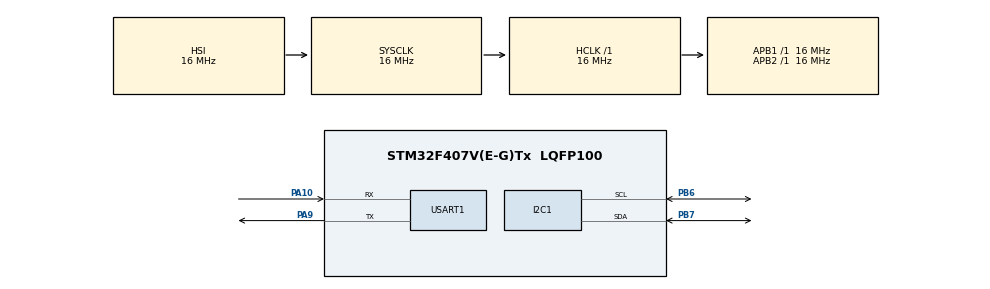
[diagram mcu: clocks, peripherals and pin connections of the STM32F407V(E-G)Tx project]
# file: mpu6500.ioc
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FREERTOS.Queues01=imuQueue,16,ImuMsg,0,Static,imuQueueBuffer,imuQueueControlBlock
FREERTOS.Tasks01=SensorTask,40,128,StartSensorTask,Default,NULL,Static,SensorTaskBuffer,SensorTaskControlBlock;TelemetryTask,24,128,StartTelemetryTask,Default,NULL,Static,TelemetryTaskBuffer,TelemetryTaskControlBlock
I2C1.I2C_Mode=I2C_Fast
Mcu.Family=STM32F4
Mcu.Name=STM32F407V(E-G)Tx
Mcu.Package=LQFP100
NVIC.PriorityGroup=NVIC_PRIORITYGROUP_4
NVIC.TIM6_DAC_IRQn=true\:15\:0\:false\:false\:true\:false\:false\:true\:true
NVIC.TimeBase=TIM6_DAC_IRQn
NVIC.TimeBaseIP=TIM6
PA10.Mode=Asynchronous
PA10.Signal=USART1_RX
PA9.Mode=Asynchronous
PA9.Signal=USART1_TX
PB6.GPIO_Pu=GPIO_PULLUP
PB6.Mode=I2C
PB6.Signal=I2C1_SCL
PB7.GPIO_Pu=GPIO_PULLUP
PB7.Mode=I2C
PB7.Signal=I2C1_SDA
ProjectManager.HeapSize=0x200
ProjectManager.StackSize=0x400
ProjectManager.TargetToolchain=CMake
RCC.AHBFreq_Value=16000000
RCC.APB1Freq_Value=16000000
RCC.APB2Freq_Value=16000000
RCC.CortexFreq_Value=16000000
RCC.HSE_VALUE=25000000
RCC.HSI_VALUE=16000000
RCC.LSE_VALUE=32768
RCC.SYSCLKFreq_VALUE=16000000
RCC.VCOOutputFreq_Value=192000000
USART1.VirtualMode=VM_ASYNC
VP_FREERTOS_VS_CMSIS_V2.Mode=CMSIS_V2
VP_SYS_VS_tim6.Mode=TIM6
board=custom

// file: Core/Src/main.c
/* USER CODE BEGIN Header */
/**
 ******************************************************************************
 * @file           : main.c
 * @brief          : Main program body
 ******************************************************************************
 * @attention
 *
 * Copyright (c) 2026 STMicroelectronics.
 * All rights reserved.
 *
 * This software is licensed under terms that can be found in the LICENSE file
 * in the root directory of this software component.
 * If no LICENSE file comes with this software, it is provided AS-IS.
 *
 ******************************************************************************
 */
/* USER CODE END Header */
#include "main.h"
#include "cmsis_os.h"

/* USER CODE BEGIN Includes */
#include "app.hpp"
#include "ImuMsg.h"

/* USER CODE END Includes */

typedef StaticTask_t osStaticThreadDef_t;
typedef StaticQueue_t osStaticMessageQDef_t;

I2C_HandleTypeDef hi2c1;

UART_HandleTypeDef huart1;

/* Definitions for SensorTask */
osThreadId_t SensorTaskHandle;
uint32_t SensorTaskBuffer[128];
osStaticThreadDef_t SensorTaskControlBlock;
const osThreadAttr_t SensorTask_attributes = {
    .name = "SensorTask",
    .cb_mem = &SensorTaskControlBlock,
    .cb_size = sizeof(SensorTaskControlBlock),
    .stack_mem = &SensorTaskBuffer[0],
    .stack_size = sizeof(SensorTaskBuffer),
    .priority = (osPriority_t)osPriorityHigh,
};
/* Definitions for TelemetryTask */
osThreadId_t TelemetryTaskHandle;
uint32_t TelemetryTaskBuffer[128];
osStaticThreadDef_t TelemetryTaskControlBlock;
const osThreadAttr_t TelemetryTask_attributes = {
    .name = "TelemetryTask",
    .cb_mem = &TelemetryTaskControlBlock,
    .cb_size = sizeof(TelemetryTaskControlBlock),
    .stack_mem = &TelemetryTaskBuffer[0],
    .stack_size = sizeof(TelemetryTaskBuffer),
    .priority = (osPriority_t)osPriorityNormal,
};
/* Definitions for imuQueue */
osMessageQueueId_t imuQueueHandle;
uint8_t imuQueueBuffer[16 * sizeof(ImuMsg)];
osStaticMessageQDef_t imuQueueControlBlock;
const osMessageQueueAttr_t imuQueue_attributes = {
    .name = "imuQueue",
    .cb_mem = &imuQueueControlBlock,
    .cb_size = sizeof(imuQueueControlBlock),
    .mq_mem = &imuQueueBuffer,
    .mq_size = sizeof(imuQueueBuffer)};

void SystemClock_Config(void);
static void MX_GPIO_Init(void);
static void MX_I2C1_Init(void);
static void MX_USART1_UART_Init(void);
void StartSensorTask(void *argument);
void StartTelemetryTask(void *argument);

int main(void)
{

  /* MCU Configuration--------------------------------------------------------*/

  /* Reset of all peripherals, Initializes the Flash interface and the Systick. */
  HAL_Init();

  /* Configure the system clock */
  SystemClock_Config();

  /* Initialize all configured peripherals */
  MX_GPIO_Init();
  MX_I2C1_Init();
  MX_USART1_UART_Init();
  /* USER CODE BEGIN 2 */
  // appMain(); // during the mpu alone test
  /* USER CODE END 2 */

  /* Init scheduler */
  osKernelInitialize();

  /* Create the queue(s) */
  /* creation of imuQueue */
  imuQueueHandle = osMessageQueueNew(16, sizeof(ImuMsg), &imuQueue_attributes);

  /* Create the thread(s) */
  /* creation of SensorTask */
  SensorTaskHandle = osThreadNew(StartSensorTask, NULL, &SensorTask_attributes);

  /* creation of TelemetryTask */
  TelemetryTaskHandle = osThreadNew(StartTelemetryTask, NULL, &TelemetryTask_attributes);

  /* Start scheduler */
  osKernelStart();

  /* We should never get here as control is now taken by the scheduler */

  /* Infinite loop */
  while (1)
  {

  }
}

void SystemClock_Config(void)
{
  RCC_OscInitTypeDef RCC_OscInitStruct = {0};
  RCC_ClkInitTypeDef RCC_ClkInitStruct = {0};

  /** Configure the main internal regulator output voltage
   */
  __HAL_RCC_PWR_CLK_ENABLE();
  __HAL_PWR_VOLTAGESCALING_CONFIG(PWR_REGULATOR_VOLTAGE_SCALE1);

  /** Initializes the RCC Oscillators according to the specified parameters
   * in the RCC_OscInitTypeDef structure.
   */
  RCC_OscInitStruct.OscillatorType = RCC_OSCILLATORTYPE_HSI;
  RCC_OscInitStruct.HSIState = RCC_HSI_ON;
  RCC_OscInitStruct.HSICalibrationValue = RCC_HSICALIBRATION_DEFAULT;
  RCC_OscInitStruct.PLL.PLLState = RCC_PLL_NONE;
  if (HAL_RCC_OscConfig(&RCC_OscInitStruct) != HAL_OK)
  {
    Error_Handler();
  }

  /** Initializes the CPU, AHB and APB buses clocks
   */
  RCC_ClkInitStruct.ClockType = RCC_CLOCKTYPE_HCLK | RCC_CLOCKTYPE_SYSCLK | RCC_CLOCKTYPE_PCLK1 | RCC_CLOCKTYPE_PCLK2;
  RCC_ClkInitStruct.SYSCLKSource = RCC_SYSCLKSOURCE_HSI;
  RCC_ClkInitStruct.AHBCLKDivider = RCC_SYSCLK_DIV1;
  RCC_ClkInitStruct.APB1CLKDivider = RCC_HCLK_DIV1;
  RCC_ClkInitStruct.APB2CLKDivider = RCC_HCLK_DIV1;

  if (HAL_RCC_ClockConfig(&RCC_ClkInitStruct, FLASH_LATENCY_0) != HAL_OK)
  {
    Error_Handler();
  }
}

static void MX_I2C1_Init(void)
{

  hi2c1.Instance = I2C1;
  hi2c1.Init.ClockSpeed = 400000;
  hi2c1.Init.DutyCycle = I2C_DUTYCYCLE_2;
  hi2c1.Init.OwnAddress1 = 0;
  hi2c1.Init.AddressingMode = I2C_ADDRESSINGMODE_7BIT;
  hi2c1.Init.DualAddressMode = I2C_DUALADDRESS_DISABLE;
  hi2c1.Init.OwnAddress2 = 0;
  hi2c1.Init.GeneralCallMode = I2C_GENERALCALL_DISABLE;
  hi2c1.Init.NoStretchMode = I2C_NOSTRETCH_DISABLE;
  if (HAL_I2C_Init(&hi2c1) != HAL_OK)
  {
    Error_Handler();
  }
}

static void MX_USART1_UART_Init(void)
{

  huart1.Instance = USART1;
  huart1.Init.BaudRate = 115200;
  huart1.Init.WordLength = UART_WORDLENGTH_8B;
  huart1.Init.StopBits = UART_STOPBITS_1;
  huart1.Init.Parity = UART_PARITY_NONE;
  huart1.Init.Mode = UART_MODE_TX_RX;
  huart1.Init.HwFlowCtl = UART_HWCONTROL_NONE;
  huart1.Init.OverSampling = UART_OVERSAMPLING_16;
  if (HAL_UART_Init(&huart1) != HAL_OK)
  {
    Error_Handler();
  }
}

static void MX_GPIO_Init(void)
{

  /* GPIO Ports Clock Enable */
  __HAL_RCC_GPIOA_CLK_ENABLE();
  __HAL_RCC_GPIOB_CLK_ENABLE();

}

void StartSensorTask(void *argument)
{
  /* USER CODE BEGIN 5 */
  /* Infinite loop */
  runSensorTask();
  /* USER CODE END 5 */
}

void StartTelemetryTask(void *argument)
{
  /* USER CODE BEGIN StartTelemetryTask */
  /* Infinite loop */
  runTelemetryTask();
  /* USER CODE END StartTelemetryTask */
}

void HAL_TIM_PeriodElapsedCallback(TIM_HandleTypeDef *htim)
{
  if (htim->Instance == TIM6)
  {
    HAL_IncTick();
  }
}

void Error_Handler(void)
{
  __disable_irq();
  while (1)
  {
  }
}
